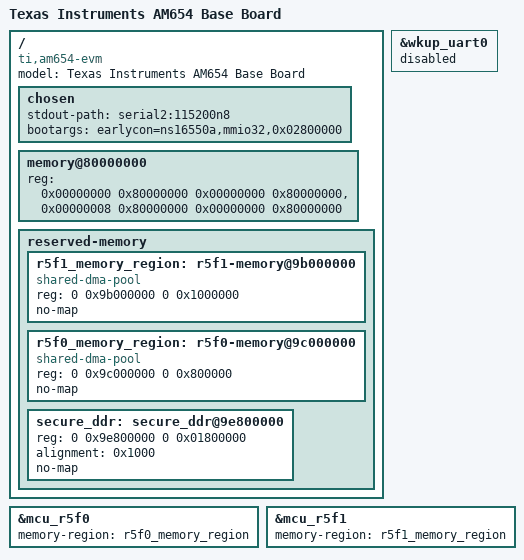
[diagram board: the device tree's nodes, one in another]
// SPDX-License-Identifier: GPL-2.0
/*
 * Copyright (C) 2016-2018 Texas Instruments Incorporated - http://www.ti.com/
 */

/dts-v1/;

#include "k3-am654.dtsi"

/ {
	compatible =  "ti,am654-evm", "ti,am654";
	model = "Texas Instruments AM654 Base Board";

	chosen {
		stdout-path = "serial2:115200n8";
		bootargs = "earlycon=ns16550a,mmio32,0x02800000";
	};

	memory@80000000 {
		device_type = "memory";
		/* 4G RAM */
		reg = <0x00000000 0x80000000 0x00000000 0x80000000>,
		      <0x00000008 0x80000000 0x00000000 0x80000000>;
	};

	reserved-memory {
		#address-cells = <2>;
		#size-cells = <2>;
		ranges;

		r5f1_memory_region: r5f1-memory@9b000000 {
			compatible = "shared-dma-pool";
			reg = <0 0x9b000000 0 0x1000000>;
			no-map;
		};

		r5f0_memory_region: r5f0-memory@9c000000 {
			compatible = "shared-dma-pool";
			reg = <0 0x9c000000 0 0x800000>;
			no-map;
		};

		secure_ddr: secure_ddr@9e800000 {
			reg = <0 0x9e800000 0 0x01800000>; /* for OP-TEE */
			alignment = <0x1000>;
			no-map;
		};
	};
};

&wkup_uart0 {
	/* Wakeup UART is used by System firmware */
	status = "disabled";
};

&mcu_r5f0 {
	memory-region = <&r5f0_memory_region>;
};

&mcu_r5f1 {
	memory-region = <&r5f1_memory_region>;
};
